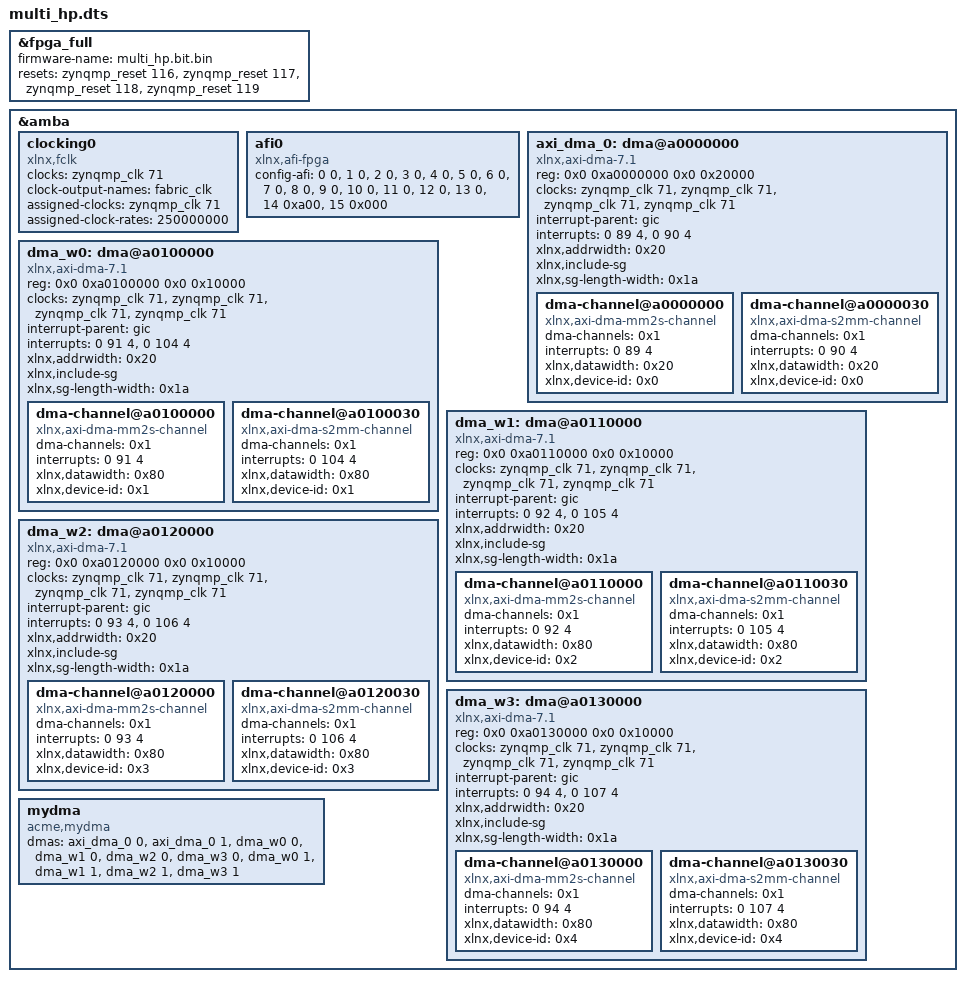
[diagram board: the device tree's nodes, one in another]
// Device tree overlay for the multi_hp PL design on the KV260
// (PetaLinux 2022.2): the memory_thing loopback DMA (now the activation
// engine) plus four weight DMAs, one per HP port, each built as a loopback
// test lane through axis_incrementer (marked [lb]; see dma_w0 for the sink
// variant).
// Loaded by `xmutil loadapp multi_hp`.
//
// Compile on the board:  dtc -@ -I dts -O dtb -o multi_hp.dtbo multi_hp.dts
//
// The addresses and interrupt numbers below assume the block design in the
// walkthrough: weight DMA AXI-Lite at 0xA010_0000 + i * 0x1_0000,
// mm2s_introut of dma_w0..w3 on pl_ps_irq0[2..5] (GIC SPI 91..94), and on
// loopback lanes s2mm_introut on pl_ps_irq1[0..3] (GIC SPI 104..107). If your
// Address Editor or xlconcat differs, change them here to match; the
// XSCT-generated .dtsi for the new design is the reference.
//
// Everything in the PL runs from pl_clk0 at 250 MHz in this design.
/dts-v1/;
/plugin/;

/ {
	/* Fragment 0: program the PL with the bitstream in this app's folder. */
	fragment@0 {
		target = <&fpga_full>;
		__overlay__ {
			#address-cells = <2>;
			#size-cells = <2>;
			firmware-name = "multi_hp.bit.bin";
			resets = <&zynqmp_reset 116>, <&zynqmp_reset 117>,
				 <&zynqmp_reset 118>, <&zynqmp_reset 119>;
		};
	};

	/* Fragment 1: describe what is in the PL, under the PS's AXI bus. */
	fragment@1 {
		target = <&amba>;
		__overlay__ {
			#address-cells = <2>;
			#size-cells = <2>;

			/*
			 * PL clock 0 (pl_clk0), which drives the DMA. Set this to the
			 * frequency configured for pl_clk0 in your Vivado design.
			 */
			clocking0: clocking0 {
				compatible = "xlnx,fclk";
				#clock-cells = <0>;
				clocks = <&zynqmp_clk 71>;
				clock-output-names = "fabric_clk";
				assigned-clocks = <&zynqmp_clk 71>;
				assigned-clock-rates = <250000000>;	/* 250 MHz: match pl_clk0 in Vivado */
			};

			/*
			 * PS-PL AXI port widths. 0 = 128-bit (Vivado's default for the
			 * HP ports), 1 = 64-bit, 2 = 32-bit. Pairs are <register value>;
			 * if you changed the width of the HP port the DMA masters through,
			 * set its entries to match.
			 */
			afi0: afi0 {
				compatible = "xlnx,afi-fpga";
				config-afi = <0 0>, <1 0>, <2 0>, <3 0>, <4 0>, <5 0>,
					     <6 0>, <7 0>, <8 0>, <9 0>, <10 0>, <11 0>,
					     <12 0>, <13 0>, <14 0xa00>, <15 0x000>;
			};

			axi_dma_0: dma@a0000000 {
				compatible = "xlnx,axi-dma-7.1", "xlnx,axi-dma-1.00.a";
				reg = <0x0 0xa0000000 0x0 0x20000>;
				#dma-cells = <1>;
				clock-names = "s_axi_lite_aclk", "m_axi_sg_aclk", "m_axi_mm2s_aclk", "m_axi_s2mm_aclk";
				clocks = <&zynqmp_clk 71>, <&zynqmp_clk 71>, <&zynqmp_clk 71>, <&zynqmp_clk 71>;
				interrupt-names = "mm2s_introut", "s2mm_introut";
				interrupt-parent = <&gic>;
				interrupts = <0 89 4>, <0 90 4>;	/* pl_ps_irq0[0], [1] */
				xlnx,addrwidth = <0x20>;
				xlnx,include-sg;
				xlnx,sg-length-width = <0x1a>;	/* 26 bits: max 64 MiB - 1 per transfer */

				dma-channel@a0000000 {
					compatible = "xlnx,axi-dma-mm2s-channel";
					dma-channels = <0x1>;
					interrupts = <0 89 4>;
					xlnx,datawidth = <0x20>;	/* MM2S stream: 32 bits */
					xlnx,device-id = <0x0>;
				};

				dma-channel@a0000030 {
					compatible = "xlnx,axi-dma-s2mm-channel";
					dma-channels = <0x1>;
					interrupts = <0 90 4>;
					xlnx,datawidth = <0x20>;	/* S2MM stream: 32 bits */
					xlnx,device-id = <0x0>;
				};
			};


			/*
			 * Weight lane 0, masters S_AXI_HP0_FPD, 128-bit. Built as a
			 * loopback test lane: MM2S -> axis_incrementer -> S2MM. For a
			 * sink lane (MM2S only), delete the S2MM entries marked [lb]
			 * and "w0rx" from the mydma node below.
			 */
			dma_w0: dma@a0100000 {
				compatible = "xlnx,axi-dma-7.1", "xlnx,axi-dma-1.00.a";
				reg = <0x0 0xa0100000 0x0 0x10000>;
				#dma-cells = <1>;
				clock-names = "s_axi_lite_aclk", "m_axi_sg_aclk", "m_axi_mm2s_aclk",
					      "m_axi_s2mm_aclk";	/* [lb] last one */
				clocks = <&zynqmp_clk 71>, <&zynqmp_clk 71>, <&zynqmp_clk 71>,
					 <&zynqmp_clk 71>;
				interrupt-names = "mm2s_introut", "s2mm_introut";	/* [lb] s2mm */
				interrupt-parent = <&gic>;
				/* pl_ps_irq0[2], and [lb] pl_ps_irq1[0] */
				interrupts = <0 91 4>, <0 104 4>;
				xlnx,addrwidth = <0x20>;
				xlnx,include-sg;
				xlnx,sg-length-width = <0x1a>;

				dma-channel@a0100000 {
					compatible = "xlnx,axi-dma-mm2s-channel";
					dma-channels = <0x1>;
					interrupts = <0 91 4>;
					xlnx,datawidth = <0x80>;	/* 128-bit stream */
					xlnx,device-id = <0x1>;
				};

				/* [lb] the S2MM side of the loopback lane */
				dma-channel@a0100030 {
					compatible = "xlnx,axi-dma-s2mm-channel";
					dma-channels = <0x1>;
					interrupts = <0 104 4>;
					xlnx,datawidth = <0x80>;
					xlnx,device-id = <0x1>;
				};
			};

			/*
			 * Weight lane 1, masters S_AXI_HP1_FPD, 128-bit. Built as a
			 * loopback test lane: MM2S -> axis_incrementer -> S2MM. For a
			 * sink lane (MM2S only), delete the S2MM entries marked [lb]
			 * and "w1rx" from the mydma node below.
			 */
			dma_w1: dma@a0110000 {
				compatible = "xlnx,axi-dma-7.1", "xlnx,axi-dma-1.00.a";
				reg = <0x0 0xa0110000 0x0 0x10000>;
				#dma-cells = <1>;
				clock-names = "s_axi_lite_aclk", "m_axi_sg_aclk", "m_axi_mm2s_aclk",
					      "m_axi_s2mm_aclk";	/* [lb] last one */
				clocks = <&zynqmp_clk 71>, <&zynqmp_clk 71>, <&zynqmp_clk 71>,
					 <&zynqmp_clk 71>;
				interrupt-names = "mm2s_introut", "s2mm_introut";	/* [lb] s2mm */
				interrupt-parent = <&gic>;
				/* pl_ps_irq0[3], and [lb] pl_ps_irq1[1] */
				interrupts = <0 92 4>, <0 105 4>;
				xlnx,addrwidth = <0x20>;
				xlnx,include-sg;
				xlnx,sg-length-width = <0x1a>;

				dma-channel@a0110000 {
					compatible = "xlnx,axi-dma-mm2s-channel";
					dma-channels = <0x1>;
					interrupts = <0 92 4>;
					xlnx,datawidth = <0x80>;	/* 128-bit stream */
					xlnx,device-id = <0x2>;
				};

				/* [lb] the S2MM side of the loopback lane */
				dma-channel@a0110030 {
					compatible = "xlnx,axi-dma-s2mm-channel";
					dma-channels = <0x1>;
					interrupts = <0 105 4>;
					xlnx,datawidth = <0x80>;
					xlnx,device-id = <0x2>;
				};
			};

			/*
			 * Weight lane 2, masters S_AXI_HP2_FPD, 128-bit. Built as a
			 * loopback test lane: MM2S -> axis_incrementer -> S2MM. For a
			 * sink lane (MM2S only), delete the S2MM entries marked [lb]
			 * and "w2rx" from the mydma node below.
			 */
			dma_w2: dma@a0120000 {
				compatible = "xlnx,axi-dma-7.1", "xlnx,axi-dma-1.00.a";
				reg = <0x0 0xa0120000 0x0 0x10000>;
				#dma-cells = <1>;
				clock-names = "s_axi_lite_aclk", "m_axi_sg_aclk", "m_axi_mm2s_aclk",
					      "m_axi_s2mm_aclk";	/* [lb] last one */
				clocks = <&zynqmp_clk 71>, <&zynqmp_clk 71>, <&zynqmp_clk 71>,
					 <&zynqmp_clk 71>;
				interrupt-names = "mm2s_introut", "s2mm_introut";	/* [lb] s2mm */
				interrupt-parent = <&gic>;
				/* pl_ps_irq0[4], and [lb] pl_ps_irq1[2] */
				interrupts = <0 93 4>, <0 106 4>;
				xlnx,addrwidth = <0x20>;
				xlnx,include-sg;
				xlnx,sg-length-width = <0x1a>;

				dma-channel@a0120000 {
					compatible = "xlnx,axi-dma-mm2s-channel";
					dma-channels = <0x1>;
					interrupts = <0 93 4>;
					xlnx,datawidth = <0x80>;	/* 128-bit stream */
					xlnx,device-id = <0x3>;
				};

				/* [lb] the S2MM side of the loopback lane */
				dma-channel@a0120030 {
					compatible = "xlnx,axi-dma-s2mm-channel";
					dma-channels = <0x1>;
					interrupts = <0 106 4>;
					xlnx,datawidth = <0x80>;
					xlnx,device-id = <0x3>;
				};
			};

			/*
			 * Weight lane 3, masters S_AXI_HP3_FPD, 128-bit. Built as a
			 * loopback test lane: MM2S -> axis_incrementer -> S2MM. For a
			 * sink lane (MM2S only), delete the S2MM entries marked [lb]
			 * and "w3rx" from the mydma node below.
			 */
			dma_w3: dma@a0130000 {
				compatible = "xlnx,axi-dma-7.1", "xlnx,axi-dma-1.00.a";
				reg = <0x0 0xa0130000 0x0 0x10000>;
				#dma-cells = <1>;
				clock-names = "s_axi_lite_aclk", "m_axi_sg_aclk", "m_axi_mm2s_aclk",
					      "m_axi_s2mm_aclk";	/* [lb] last one */
				clocks = <&zynqmp_clk 71>, <&zynqmp_clk 71>, <&zynqmp_clk 71>,
					 <&zynqmp_clk 71>;
				interrupt-names = "mm2s_introut", "s2mm_introut";	/* [lb] s2mm */
				interrupt-parent = <&gic>;
				/* pl_ps_irq0[5], and [lb] pl_ps_irq1[3] */
				interrupts = <0 94 4>, <0 107 4>;
				xlnx,addrwidth = <0x20>;
				xlnx,include-sg;
				xlnx,sg-length-width = <0x1a>;

				dma-channel@a0130000 {
					compatible = "xlnx,axi-dma-mm2s-channel";
					dma-channels = <0x1>;
					interrupts = <0 94 4>;
					xlnx,datawidth = <0x80>;	/* 128-bit stream */
					xlnx,device-id = <0x4>;
				};

				/* [lb] the S2MM side of the loopback lane */
				dma-channel@a0130030 {
					compatible = "xlnx,axi-dma-s2mm-channel";
					dma-channels = <0x1>;
					interrupts = <0 107 4>;
					xlnx,datawidth = <0x80>;
					xlnx,device-id = <0x4>;
				};
			};

			/*
			 * Binds mydma.ko: tx/rx = the loopback (activation) engine,
			 * w0..w3 = the weight engines' MM2S, w0rx..w3rx = their S2MM on
			 * loopback lanes. Drop any name you haven't built (and its
			 * dmas entry); the driver skips missing names.
			 */
			mydma {
				compatible = "acme,mydma";
				dmas = <&axi_dma_0 0>, <&axi_dma_0 1>,
				       <&dma_w0 0>, <&dma_w1 0>, <&dma_w2 0>, <&dma_w3 0>,
				       <&dma_w0 1>, <&dma_w1 1>, <&dma_w2 1>, <&dma_w3 1>;
				dma-names = "tx", "rx", "w0", "w1", "w2", "w3",
					    "w0rx", "w1rx", "w2rx", "w3rx";	/* [lb] */
			};
		};
	};
};
